VERSION ""

NS_ :

BS_:

BU_: XXX

BO_ 85 CID_THGLZS: 8 XXX
 SG_ sig_vyjenc : 40|1@1+ (1,0) [0|1] "" XXX
 SG_ sig_dymuxq : 56|8@1+ (1,0) [0|255] "" XXX

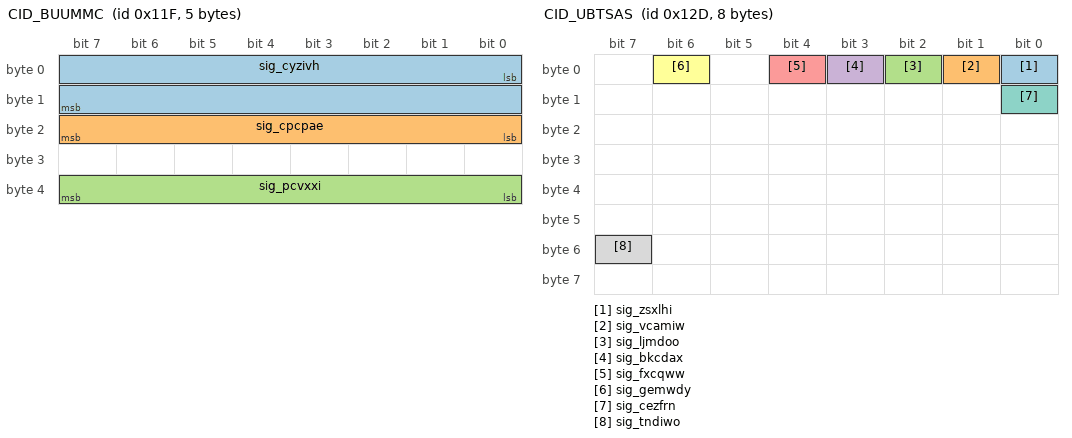
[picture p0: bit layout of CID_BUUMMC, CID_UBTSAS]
BO_ 287 CID_BUUMMC: 5 XXX
 SG_ sig_cyzivh : 0|16@1- (0.1,0) [-450|450] "" XXX
 SG_ sig_cpcpae : 16|8@1+ (4,0) [0|1020] "" XXX
 SG_ sig_pcvxxi : 32|8@1+ (1,0) [0|255] "" XXX

BO_ 289 CID_JEFRLV: 8 XXX
 SG_ sig_qhtzwi : 0|12@1+ (1,0) [0|255] "" XXX

BO_ 301 CID_UBTSAS: 8 XXX
 SG_ sig_zsxlhi : 0|1@0+ (1,0) [0|1] "" XXX
 SG_ sig_vcamiw : 1|1@0+ (1,0) [0|1] "" XXX
 SG_ sig_ljmdoo : 2|1@0+ (1,0) [0|1] "" XXX
 SG_ sig_bkcdax : 3|1@0+ (1,0) [0|1] "" XXX
 SG_ sig_fxcqww : 4|1@0+ (1,0) [0|1] "" XXX
 SG_ sig_gemwdy : 6|1@0+ (1,0) [0|1] "" XXX
 SG_ sig_cezfrn : 8|1@0+ (1,0) [0|1] "" XXX
 SG_ sig_tndiwo : 55|1@0+ (1,0) [0|1] "" XXX

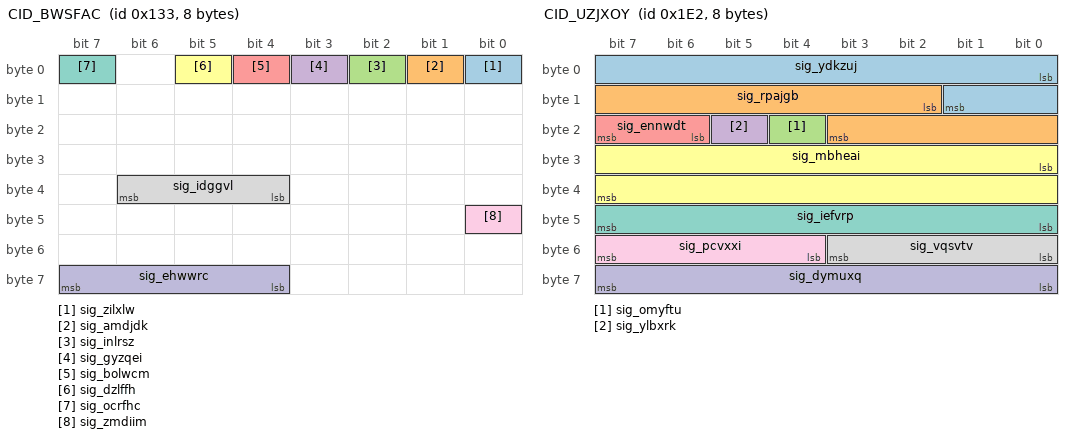
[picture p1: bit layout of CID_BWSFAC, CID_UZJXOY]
BO_ 307 CID_BWSFAC: 8 XXX
 SG_ sig_zilxlw : 0|1@0+ (1,0) [0|1] "" XXX
 SG_ sig_amdjdk : 1|1@1+ (1,0) [0|1] "" XXX
 SG_ sig_inlrsz : 2|1@1+ (1,0) [0|1] "" XXX
 SG_ sig_gyzqei : 3|1@1+ (1,0) [0|1] "" XXX
 SG_ sig_bolwcm : 4|1@0+ (1,0) [0|1] "" XXX
 SG_ sig_dzlffh : 5|1@0+ (1,0) [0|1] "" XXX
 SG_ sig_ocrfhc : 7|1@0+ (1,0) [0|1] "" XXX
 SG_ sig_idggvl : 36|3@1+ (1,0) [0|7] "" XXX
 SG_ sig_zmdiim : 40|1@0+ (1,0) [0|1] "" XXX
 SG_ sig_ehwwrc : 63|4@0+ (1,0) [0|15] "" XXX

BO_ 482 CID_UZJXOY: 8 XXX
 SG_ sig_ydkzuj : 0|10@1- (0.01,0) [0|5] "" XXX
 SG_ sig_rpajgb : 10|10@1- (0.01,0) [-5|0] "" XXX
 SG_ sig_omyftu : 20|1@0+ (1,0) [0|1] "" XXX
 SG_ sig_ylbxrk : 21|1@0+ (1,0) [0|1] "" XXX
 SG_ sig_ennwdt : 22|2@1+ (1,0) [0|1] "" XXX
 SG_ sig_mbheai : 24|16@1- (0.1,0) [-780|779.9] "" XXX
 SG_ sig_iefvrp : 47|8@0+ (1,0) [0|255] "" XXX
 SG_ sig_vqsvtv : 48|4@1+ (1,0) [0|15] "" XXX
 SG_ sig_pcvxxi : 52|4@1+ (1,0) [0|15] "" XXX
 SG_ sig_dymuxq : 56|8@1+ (1,0) [0|255] "" XXX

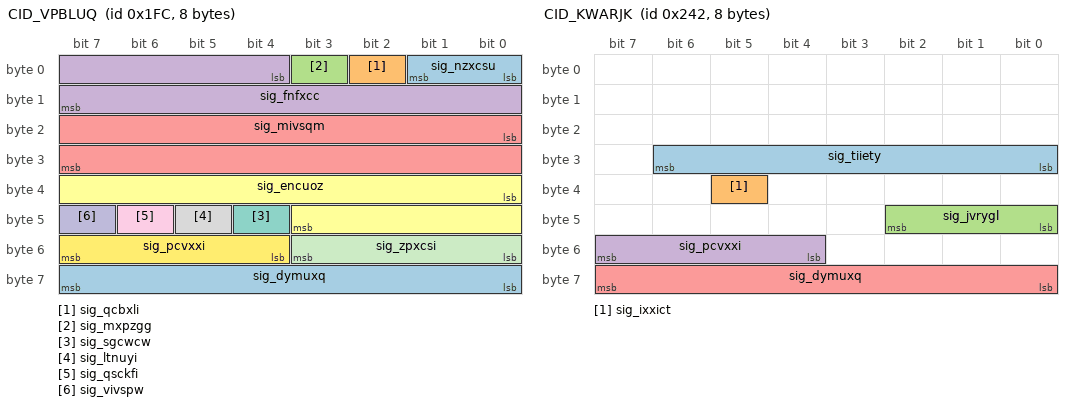
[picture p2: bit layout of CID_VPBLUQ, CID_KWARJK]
BO_ 508 CID_VPBLUQ: 8 XXX
 SG_ sig_nzxcsu : 0|2@1+ (1,0) [0|1] "" XXX
 SG_ sig_qcbxli : 2|1@1+ (1,0) [0|1] "" XXX
 SG_ sig_mxpzgg : 3|1@0+ (1,0) [0|1] "" XXX
 SG_ sig_fnfxcc : 4|12@1- (1,0) [-2048|2047] "" XXX
 SG_ sig_mivsqm : 16|16@1- (0.1,0) [-780|779.9] "Deg" XXX
 SG_ sig_encuoz : 32|12@1- (0.01,0) [0|63] "" XXX
 SG_ sig_sgcwcw : 44|1@0+ (1,0) [0|1] "" XXX
 SG_ sig_ltnuyi : 45|1@1+ (1,0) [0|255] "" XXX
 SG_ sig_qsckfi : 46|1@1+ (1,0) [0|1] "" XXX
 SG_ sig_vivspw : 47|1@0+ (1,0) [0|3] "" XXX
 SG_ sig_zpxcsi : 48|4@1+ (1,0) [0|15] "" XXX
 SG_ sig_pcvxxi : 52|4@1+ (1,0) [0|15] "" XXX
 SG_ sig_dymuxq : 56|8@1+ (1,0) [0|255] "" XXX

BO_ 578 CID_KWARJK: 8 XXX
 SG_ sig_tiiety : 30|7@0+ (1,0) [0|127] "" XXX
 SG_ sig_ixxict : 37|1@0+ (1,0) [0|1] "" XXX
 SG_ sig_jvrygl : 40|3@1+ (1,0) [0|7] "" XXX
 SG_ sig_pcvxxi : 55|4@0+ (1,0) [0|15] "" XXX
 SG_ sig_dymuxq : 56|8@1+ (1,0) [0|255] "" XXX

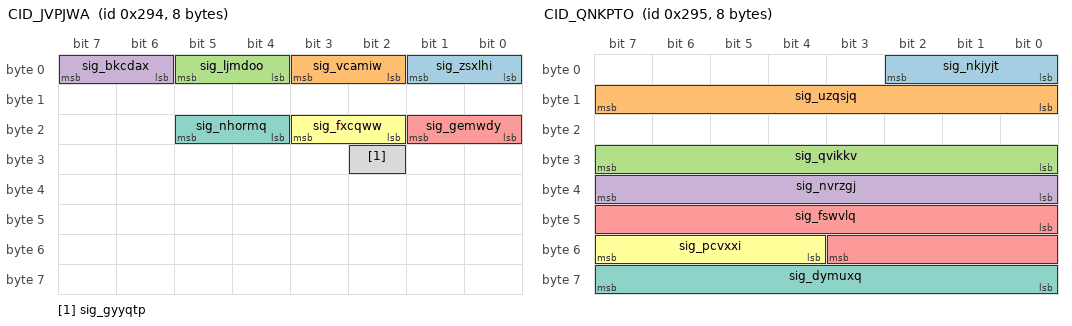
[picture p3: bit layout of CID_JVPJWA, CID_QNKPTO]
BO_ 660 CID_JVPJWA: 8 XXX
 SG_ sig_zsxlhi : 1|2@0+ (1,0) [0|3] "" XXX
 SG_ sig_vcamiw : 3|2@0+ (1,0) [0|3] "" XXX
 SG_ sig_ljmdoo : 5|2@0+ (1,0) [0|3] "" XXX
 SG_ sig_bkcdax : 7|2@0+ (1,0) [0|3] "" XXX
 SG_ sig_gemwdy : 17|2@0+ (1,0) [0|3] "" XXX
 SG_ sig_fxcqww : 19|2@0+ (1,0) [0|3] "" XXX
 SG_ sig_nhormq : 21|2@0+ (1,0) [0|3] "" XXX
 SG_ sig_gyyqtp : 26|1@0+ (1,0) [0|1] "" XXX

BO_ 661 CID_QNKPTO: 8 XXX
 SG_ sig_nkjyjt : 2|3@0+ (1,0) [0|7] "" XXX
 SG_ sig_uzqsjq : 15|8@0+ (1,0) [0|255] "" XXX
 SG_ sig_qvikkv : 31|8@0+ (1,0) [0|255] "" XXX
 SG_ sig_nvrzgj : 32|8@1+ (1,0) [0|255] "" XXX
 SG_ sig_fswvlq : 40|12@1+ (1,0) [0|255] "" XXX
 SG_ sig_pcvxxi : 52|4@1+ (1,0) [0|15] "" XXX
 SG_ sig_dymuxq : 63|8@0+ (1,0) [0|255] "" XXX

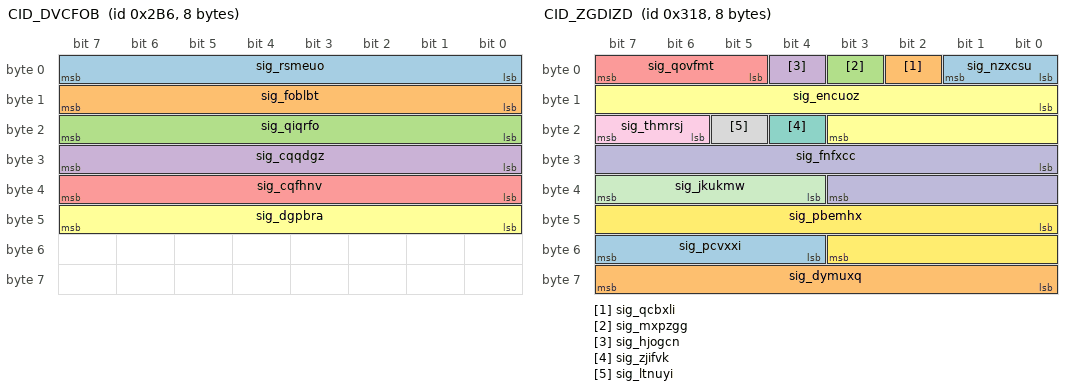
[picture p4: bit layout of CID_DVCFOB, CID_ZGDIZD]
BO_ 694 CID_DVCFOB: 8 XXX
 SG_ sig_rsmeuo : 7|8@0+ (1,0) [0|255] "" XXX
 SG_ sig_foblbt : 15|8@0+ (1,0) [0|255] "" XXX
 SG_ sig_qiqrfo : 23|8@0+ (1,0) [0|255] "" XXX
 SG_ sig_cqqdgz : 31|8@0+ (1,0) [0|255] "" XXX
 SG_ sig_cqfhnv : 39|8@0+ (1,0) [0|255] "" XXX
 SG_ sig_dgpbra : 47|8@0+ (1,0) [0|255] "" XXX

BO_ 790 CID_LOPIHS: 8 XXX
 SG_ sig_ntdiqy : 3|4@0+ (1,0) [0|1] "" XXX
 SG_ sig_rgizcs : 4|2@1+ (1,0) [0|3] "" XXX
 SG_ sig_qexpvr : 6|2@1+ (1,0) [0|3] "" XXX
 SG_ sig_swvdtn : 8|2@1+ (1,0) [0|3] "" XXX
 SG_ sig_hblfvt : 10|1@1+ (1,0) [0|1] "" XXX
 SG_ sig_waqwfv : 11|4@1+ (1,0) [0|1] "" XXX
 SG_ sig_umavkz : 15|1@0+ (1,0) [0|1] "" XXX
 SG_ sig_mbheai : 16|11@1- (1,0) [-1024|1023] "" XXX
 SG_ sig_omyftu : 27|1@1+ (1,0) [0|1] "" XXX
 SG_ sig_ylbxrk : 28|1@1+ (1,0) [0|3] "" XXX
 SG_ sig_nuypvm : 29|1@0+ (1,0) [0|1] "" XXX
 SG_ sig_llxehv : 30|1@0+ (1,0) [0|1] "" XXX
 SG_ sig_mxurei : 31|1@0+ (1,0) [0|1] "" XXX
 SG_ sig_xdrebn : 32|2@1+ (1,0) [0|3] "" XXX
 SG_ sig_hqmfmm : 34|2@1+ (1,0) [0|3] "" XXX
 SG_ sig_znmbnn : 36|4@1+ (1,0) [0|3] "" XXX
 SG_ sig_bljmlb : 40|8@1+ (5,-5) [-5|1270] "" XXX
 SG_ sig_tulqzb : 49|2@0+ (1,0) [0|3] "" XXX
 SG_ sig_yvpntd : 51|2@0+ (1,0) [0|3] "" XXX
 SG_ sig_pcvxxi : 52|4@1+ (1,0) [0|15] "" XXX
 SG_ sig_dymuxq : 56|8@1+ (1,0) [0|15] "" XXX

BO_ 792 CID_ZGDIZD: 8 XXX
 SG_ sig_nzxcsu : 0|2@1+ (1,0) [0|1] "" XXX
 SG_ sig_qcbxli : 2|1@1+ (1,0) [0|1] "" XXX
 SG_ sig_mxpzgg : 3|1@1+ (1,0) [0|1] "" XXX
 SG_ sig_hjogcn : 4|1@1+ (1,0) [0|1] "" XXX
 SG_ sig_qovfmt : 5|3@1+ (1,0) [0|1] "" XXX
 SG_ sig_encuoz : 8|12@1- (1,0) [-2048|2047] "" XXX
 SG_ sig_zjifvk : 20|1@1+ (1,0) [0|1] "" XXX
 SG_ sig_ltnuyi : 21|1@1+ (1,0) [0|1] "" XXX
 SG_ sig_thmrsj : 22|2@1+ (1,0) [0|15] "" XXX
 SG_ sig_fnfxcc : 24|12@1- (1,0) [-2048|2047] "" XXX
 SG_ sig_jkukmw : 36|4@1+ (1,0) [0|15] "" XXX
 SG_ sig_pbemhx : 40|12@1+ (1,0) [0|4095] "" XXX
 SG_ sig_pcvxxi : 52|4@1+ (1,0) [0|15] "" XXX
 SG_ sig_dymuxq : 56|8@1+ (1,0) [0|255] "" XXX

BO_ 813 CID_TXJUZG: 8 XXX
 SG_ sig_akqcsd : 0|9@1+ (0.5,0) [0|255.5] "" XXX
 SG_ sig_iiyptm : 9|1@1+ (1,0) [0|1] "" XXX
 SG_ sig_kdylbi : 10|3@1+ (1,0) [0|7] "" XXX
 SG_ sig_iqcwel : 13|3@1+ (1,0) [0|7] "" XXX
 SG_ sig_qclxil : 16|1@1+ (1,0) [0|1] "" XXX
 SG_ sig_edmlbh : 17|1@1+ (1,0) [0|1] "" XXX
 SG_ sig_mxpzgg : 18|1@1+ (1,0) [0|1] "" XXX
 SG_ sig_bpivmw : 19|3@1+ (1,0) [0|1] "" XXX
 SG_ sig_iohvjb : 22|1@0+ (1,0) [0|1] "" XXX
 SG_ sig_ytvxom : 23|1@0+ (1,0) [0|1] "" XXX
 SG_ sig_swvdtn : 24|1@1+ (1,0) [0|1] "" XXX
 SG_ sig_ybcyrd : 25|7@1+ (1,0) [0|127] "" XXX
 SG_ sig_hrsvtm : 32|4@1+ (1,0) [0|15] "" XXX
 SG_ sig_wenmvt : 36|12@1+ (1,0) [0|4095] "" XXX
 SG_ sig_pcvxxi : 48|4@1+ (1,0) [0|15] "" XXX
 SG_ sig_seczbe : 55|4@0+ (1,0) [0|15] "" XXX
 SG_ sig_dymuxq : 56|8@1+ (1,0) [0|255] "" XXX

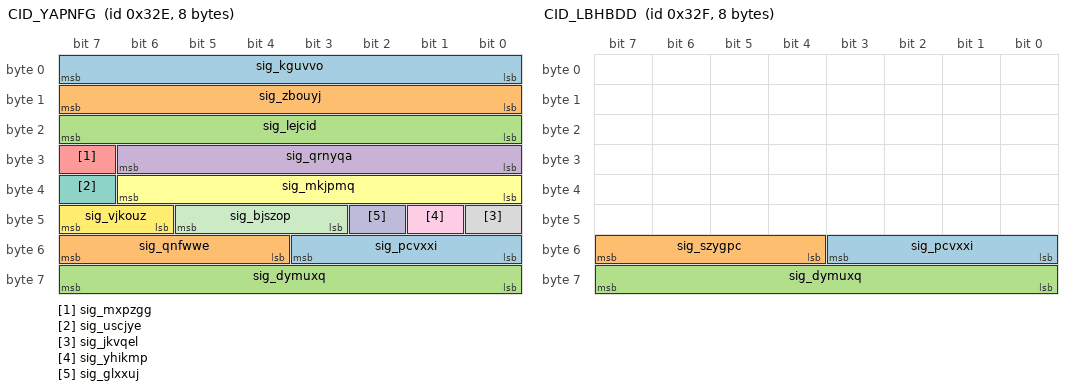
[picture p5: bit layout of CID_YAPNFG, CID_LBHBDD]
BO_ 814 CID_YAPNFG: 8 XXX
 SG_ sig_kguvvo : 0|8@1+ (0.05,-5) [-100|155] "" XXX
 SG_ sig_zbouyj : 8|8@1+ (0.05,-5) [0|1.26] "" XXX
 SG_ sig_lejcid : 16|8@1+ (0.05,-5) [0|1.26] "" XXX
 SG_ sig_qrnyqa : 24|7@1+ (0.2,0) [0|12.7] "" XXX
 SG_ sig_mxpzgg : 31|1@0+ (1,0) [0|1] "" XXX
 SG_ sig_mkjpmq : 32|7@1+ (0.2,-16) [0|12.7] "" XXX
 SG_ sig_uscjye : 39|1@0+ (1,0) [0|1] "" XXX
 SG_ sig_jkvqel : 40|1@0+ (1,0) [0|1] "" XXX
 SG_ sig_yhikmp : 41|1@0+ (1,0) [0|1] "" XXX
 SG_ sig_glxxuj : 42|1@1+ (1,0) [0|3] "" XXX
 SG_ sig_bjszop : 45|3@0+ (1,0) [0|1] "" XXX
 SG_ sig_vjkouz : 46|2@1+ (1,0) [0|3] "" XXX
 SG_ sig_pcvxxi : 48|4@1+ (1,0) [0|15] "" XXX
 SG_ sig_qnfwwe : 55|4@0+ (1,0) [0|15] "" XXX
 SG_ sig_dymuxq : 56|8@1+ (1,0) [0|255] "" XXX

BO_ 815 CID_LBHBDD: 8 XXX
 SG_ sig_pcvxxi : 48|4@1+ (1,0) [0|15] "" XXX
 SG_ sig_szygpc : 55|4@0+ (1,0) [0|15] "" XXX
 SG_ sig_dymuxq : 56|8@1+ (1,0) [0|255] "" XXX

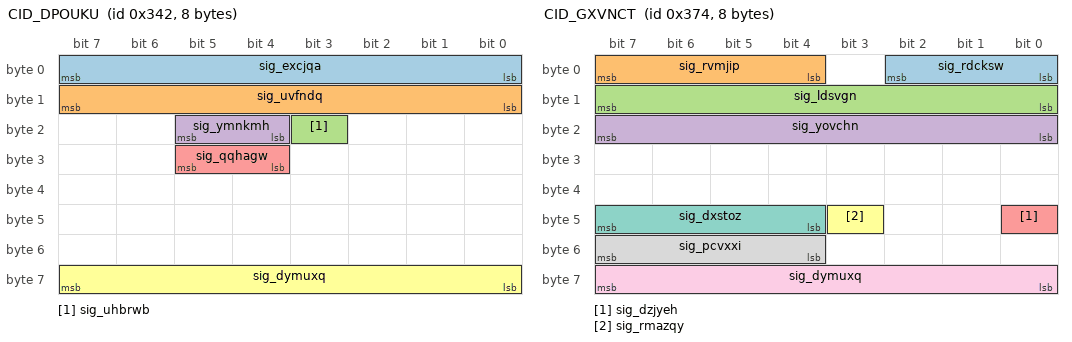
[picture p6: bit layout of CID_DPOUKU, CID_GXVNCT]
BO_ 834 CID_DPOUKU: 8 XXX
 SG_ sig_excjqa : 0|8@1+ (0.01,0) [0|2.55] "" XXX
 SG_ sig_uvfndq : 8|8@1+ (0.01,0) [0|2.55] "" XXX
 SG_ sig_uhbrwb : 19|1@1+ (1,0) [0|1] "" XXX
 SG_ sig_ymnkmh : 20|2@1+ (1,0) [0|255] "" XXX
 SG_ sig_qqhagw : 28|2@1+ (1,0) [0|1] "" XXX
 SG_ sig_dymuxq : 56|8@1+ (1,0) [0|255] "" XXX

 BO_ 884 CID_GXVNCT: 8 MRR
 SG_ sig_rdcksw : 2|3@0+ (1,0) [0|3] "" MRR
 SG_ sig_rvmjip : 7|4@0+ (1,0) [0|15] "" MRR
 SG_ sig_ldsvgn : 15|8@0+ (0.1,-12) [0|255] "" MRR
 SG_ sig_yovchn : 23|8@0+ (1,-100) [0|255] "" MRR
 SG_ sig_dzjyeh : 40|1@0+ (1,0) [0|3] "" MRR
 SG_ sig_rmazqy : 43|1@0+ (1,0) [0|1] "" XXX
 SG_ sig_dxstoz : 44|4@1+ (1,0) [0|15] "" XXX
 SG_ sig_pcvxxi : 52|4@1+ (1,0) [0|15] "" MRR
 SG_ sig_dymuxq : 56|8@1+ (1,0) [0|255] "" MRR

BO_ 944 CID_DILWKY: 8 XXX
 SG_ sig_osefks : 1|2@0+ (1,0) [0|3] "" XXX
 SG_ sig_sakiic : 2|1@0+ (1,0) [0|1] "" XXX
 SG_ sig_bdwuva : 4|2@0+ (1,0) [0|3] "" XXX
 SG_ sig_sbltsi : 5|1@0+ (1,0) [0|1] "" XXX
 SG_ sig_tgsajw : 6|1@0+ (1,0) [0|1] "" XXX
 SG_ sig_pjjsiu : 7|1@0+ (1,0) [0|1] "" XXX
 SG_ sig_koiczz : 8|1@0+ (1,0) [0|1] "" XXX
 SG_ sig_ebnpzd : 11|3@0+ (1,0) [0|7] "" XXX
 SG_ sig_qznfkc : 12|1@0+ (1,0) [0|1] "" XXX
 SG_ sig_qimfor : 14|2@0+ (1,0) [0|3] "" XXX
 SG_ sig_dotqzf : 15|1@0+ (1,0) [0|1] "" XXX
 SG_ sig_qnkdgh : 16|1@0+ (1,0) [0|1] "" XXX
 SG_ sig_kmicpl : 18|2@0+ (1,0) [0|3] "" XXX
 SG_ sig_ebfzrc : 19|1@0+ (1,0) [0|1] "" XXX
 SG_ sig_zhidus : 23|4@0+ (1,0) [0|15] "" XXX
 SG_ sig_mhzpht : 24|28@1+ (1,0) [0|268435455] "" XXX
 SG_ sig_pcvxxi : 52|4@1+ (1,0) [0|15] "" XXX
 SG_ sig_dymuxq : 56|8@1+ (1,0) [0|255] "" XXX

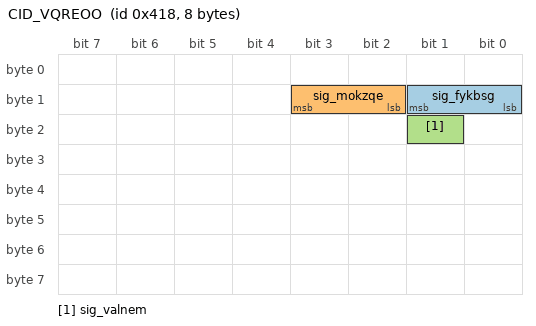
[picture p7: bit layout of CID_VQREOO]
BO_ 1048 CID_VQREOO: 8 XXX
 SG_ sig_fykbsg : 9|2@0+ (1,0) [0|1] "" XXX
 SG_ sig_mokzqe : 11|2@0+ (1,0) [0|1] "" XXX
 SG_ sig_valnem : 17|1@0+ (1,0) [0|1] "" XXX

VAL_ 578 sig_jvrygl 4 "D" 2 "R" 3 "N" 1 "P";
VAL_ 790 sig_ntdiqy 11 "AutoFullBeamActive" 2 "AutoFullBeamInactive";
VAL_ 790 sig_rgizcs 0 "GRAY" 1 "GREEN" 2 "YELLOW" 3 "RED";
VAL_ 790 sig_qexpvr 3 "ALARM_AND_LKA" 2 "LKA" 1 "ALARM" 0 "DISABLE";
VAL_ 790 sig_hqmfmm 0 "GRAY" 1 "GREEN" 2 "YELLOW" 3 "RED";
VAL_ 790 sig_tulqzb 0 "VIBRATION" 1 "AUDIO" 2 "AUDIO_AND_VIBRATION";
VAL_ 792 sig_nzxcsu 0 "NotReady" 1 "Ready" 2 "Active" 3 "TemporaryFail";
VAL_ 813 sig_kdylbi 4 "4BAR" 3 "3BAR" 2 "2BAR" 1 "1BAR";
VAL_ 813 sig_bpivmw 0 "OFF" 2 "ACC_ON" 3 "ACC_ACTIVE" 5 "FORCE_ACCEL" 7 "ERROR";
VAL_ 813 sig_ybcyrd 36 "ACC_ERROR" 22 "OVERRIDE" 12 "ENGAGE" 8 "DISENGAGE" 20 "ACC_ON" 32 "ACC_OFF" 48 "CHECK_GEAR_D" 16 "FORCE_ACCEL" 0 "NONE";
VAL_ 814 sig_bjszop 0 "Off" 1 "Passive" 2 "StandBy" 3 "ActiveControl" 4 "BrakeOnly" 5 "Override" 6 "Standstill" 7 "Failure";
VAL_ 814 sig_vjkouz 0 "Softoff" 1 "Fastoff" 2 "Immediateoff" 3 "Initial";
VAL_ 834 sig_ymnkmh 2 "SPORT" 1 "ECO" 0 "SNOW";
VAL_ 834 sig_qqhagw 3 "HEV" 2 "FORCE_EV" 1 "EV";
VAL_ 944 sig_bdwuva 0 "NOTPRESSED" 1 "DOWN_SETSPEED" 3 "UP_RESETSPEED";
